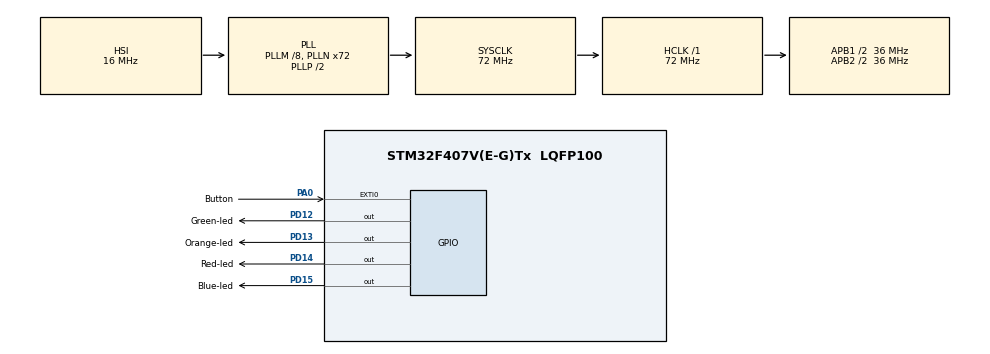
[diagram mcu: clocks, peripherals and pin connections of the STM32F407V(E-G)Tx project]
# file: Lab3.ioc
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Mcu.Family=STM32F4
Mcu.Name=STM32F407V(E-G)Tx
Mcu.Package=LQFP100
NVIC.EXTI0_IRQn=true\:1\:1\:true\:true\:true\:1\:true\:true\:true
NVIC.PriorityGroup=NVIC_PRIORITYGROUP_1
NVIC.TIM2_IRQn=true\:0\:0\:false\:true\:true\:2\:true\:true\:true
NVIC.TIM3_IRQn=true\:0\:0\:false\:true\:true\:3\:true\:true\:true
PA0-WKUP.GPIO_Label=Button
PA0-WKUP.Signal=GPXTI0
PD12.GPIO_Label=Green-led
PD12.Signal=GPIO_Output
PD13.GPIO_Label=Orange-led
PD13.Signal=GPIO_Output
PD14.GPIO_Label=Red-led
PD14.Signal=GPIO_Output
PD15.GPIO_Label=Blue-led
PD15.Signal=GPIO_Output
ProjectManager.HeapSize=0x200
ProjectManager.StackSize=0x400
ProjectManager.TargetToolchain=STM32CubeIDE
RCC.48MHZClocksFreq_Value=20571428.57142857
RCC.AHBFreq_Value=72000000
RCC.APB1CLKDivider=RCC_HCLK_DIV2
RCC.APB1Freq_Value=36000000
RCC.APB1TimFreq_Value=72000000
RCC.APB2CLKDivider=RCC_HCLK_DIV2
RCC.APB2Freq_Value=36000000
RCC.APB2TimFreq_Value=72000000
RCC.CortexFreq_Value=72000000
RCC.HCLKFreq_Value=72000000
RCC.HSE_VALUE=8000000
RCC.HSI_VALUE=16000000
RCC.LSE_VALUE=32768
RCC.PLLM=8
RCC.PLLN=72
RCC.PLLQ=7
RCC.SYSCLKFreq_VALUE=72000000
RCC.SYSCLKSource=RCC_SYSCLKSOURCE_PLLCLK
RCC.VCOOutputFreq_Value=144000000
TIM2.Period=2000
TIM2.Prescaler=35999
TIM3.Period=2000
TIM3.Prescaler=35999
VP_TIM2_VS_ClockSourceINT.Mode=Internal
VP_TIM3_VS_ClockSourceINT.Mode=Internal
board=STM32F407G-DISC1

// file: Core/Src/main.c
/* USER CODE BEGIN Header */
/**
  ******************************************************************************
  * @file           : main.c
  * @brief          : Main program body
  ******************************************************************************
  * @attention
  *
  * Copyright (c) 2024 STMicroelectronics.
  * All rights reserved.
  *
  * This software is licensed under terms that can be found in the LICENSE file
  * in the root directory of this software component.
  * If no LICENSE file comes with this software, it is provided AS-IS.
  *
  ******************************************************************************
  */
/* USER CODE END Header */
#include "main.h"

TIM_HandleTypeDef htim2;
TIM_HandleTypeDef htim3;

/* USER CODE BEGIN PV */
volatile int uzdNr = 3;
volatile int freq = 500;
/* USER CODE END PV */

void SystemClock_Config(void);
static void MX_GPIO_Init(void);
static void MX_TIM2_Init(void);
static void MX_TIM3_Init(void);
static void MX_NVIC_Init(void);

int main(void)
{

  /* MCU Configuration--------------------------------------------------------*/

  /* Reset of all peripherals, Initializes the Flash interface and the Systick. */
  HAL_Init();

  /* Configure the system clock */
  SystemClock_Config();

  /* Initialize all configured peripherals */
  MX_GPIO_Init();
  MX_TIM2_Init();
  MX_TIM3_Init();

  /* Initialize interrupts */
  MX_NVIC_Init();
  /* USER CODE BEGIN 2 */
  HAL_TIM_Base_Start_IT(&htim2);
  HAL_TIM_Base_Start_IT(&htim3);

  /* USER CODE END 2 */

  /* Infinite loop */
  /* USER CODE BEGIN WHILE */
  while (1)
  {
	  if(uzdNr == 2){
		  HAL_GPIO_WritePin(GPIOD, Orange_led_Pin, GPIO_PIN_SET);
		  HAL_Delay(freq);
		  HAL_GPIO_WritePin(GPIOD, Orange_led_Pin, GPIO_PIN_RESET);
		  HAL_Delay(freq);
	  }
    /* USER CODE END WHILE */

  }
}

void SystemClock_Config(void)
{
  RCC_OscInitTypeDef RCC_OscInitStruct = {0};
  RCC_ClkInitTypeDef RCC_ClkInitStruct = {0};

  /** Configure the main internal regulator output voltage
  */
  __HAL_RCC_PWR_CLK_ENABLE();
  __HAL_PWR_VOLTAGESCALING_CONFIG(PWR_REGULATOR_VOLTAGE_SCALE1);

  /** Initializes the RCC Oscillators according to the specified parameters
  * in the RCC_OscInitTypeDef structure.
  */
  RCC_OscInitStruct.OscillatorType = RCC_OSCILLATORTYPE_HSI;
  RCC_OscInitStruct.HSIState = RCC_HSI_ON;
  RCC_OscInitStruct.HSICalibrationValue = RCC_HSICALIBRATION_DEFAULT;
  RCC_OscInitStruct.PLL.PLLState = RCC_PLL_ON;
  RCC_OscInitStruct.PLL.PLLSource = RCC_PLLSOURCE_HSI;
  RCC_OscInitStruct.PLL.PLLM = 8;
  RCC_OscInitStruct.PLL.PLLN = 72;
  RCC_OscInitStruct.PLL.PLLP = RCC_PLLP_DIV2;
  RCC_OscInitStruct.PLL.PLLQ = 7;
  if (HAL_RCC_OscConfig(&RCC_OscInitStruct) != HAL_OK)
  {
    Error_Handler();
  }

  /** Initializes the CPU, AHB and APB buses clocks
  */
  RCC_ClkInitStruct.ClockType = RCC_CLOCKTYPE_HCLK|RCC_CLOCKTYPE_SYSCLK
                              |RCC_CLOCKTYPE_PCLK1|RCC_CLOCKTYPE_PCLK2;
  RCC_ClkInitStruct.SYSCLKSource = RCC_SYSCLKSOURCE_PLLCLK;
  RCC_ClkInitStruct.AHBCLKDivider = RCC_SYSCLK_DIV1;
  RCC_ClkInitStruct.APB1CLKDivider = RCC_HCLK_DIV2;
  RCC_ClkInitStruct.APB2CLKDivider = RCC_HCLK_DIV2;

  if (HAL_RCC_ClockConfig(&RCC_ClkInitStruct, FLASH_LATENCY_2) != HAL_OK)
  {
    Error_Handler();
  }
}

/**
  * @brief NVIC Configuration.
  * @retval None
  */
static void MX_NVIC_Init(void)
{
  /* EXTI0_IRQn interrupt configuration */
  HAL_NVIC_SetPriority(EXTI0_IRQn, 1, 1);
  HAL_NVIC_EnableIRQ(EXTI0_IRQn);
  /* TIM2_IRQn interrupt configuration */
  HAL_NVIC_SetPriority(TIM2_IRQn, 0, 0);
  HAL_NVIC_EnableIRQ(TIM2_IRQn);
  /* TIM3_IRQn interrupt configuration */
  HAL_NVIC_SetPriority(TIM3_IRQn, 0, 0);
  HAL_NVIC_EnableIRQ(TIM3_IRQn);
}

static void MX_TIM2_Init(void)
{

  TIM_ClockConfigTypeDef sClockSourceConfig = {0};
  TIM_MasterConfigTypeDef sMasterConfig = {0};

  htim2.Instance = TIM2;
  htim2.Init.Prescaler = 35999;
  htim2.Init.CounterMode = TIM_COUNTERMODE_UP;
  htim2.Init.Period = 2000; // 2000 - 1 sekunde
  htim2.Init.ClockDivision = TIM_CLOCKDIVISION_DIV1;
  htim2.Init.AutoReloadPreload = TIM_AUTORELOAD_PRELOAD_DISABLE;
  if (HAL_TIM_Base_Init(&htim2) != HAL_OK)
  {
    Error_Handler();
  }
  sClockSourceConfig.ClockSource = TIM_CLOCKSOURCE_INTERNAL;
  if (HAL_TIM_ConfigClockSource(&htim2, &sClockSourceConfig) != HAL_OK)
  {
    Error_Handler();
  }
  sMasterConfig.MasterOutputTrigger = TIM_TRGO_RESET;
  sMasterConfig.MasterSlaveMode = TIM_MASTERSLAVEMODE_DISABLE;
  if (HAL_TIMEx_MasterConfigSynchronization(&htim2, &sMasterConfig) != HAL_OK)
  {
    Error_Handler();
  }

}

static void MX_TIM3_Init(void)
{

  TIM_ClockConfigTypeDef sClockSourceConfig = {0};
  TIM_MasterConfigTypeDef sMasterConfig = {0};

  htim3.Instance = TIM3;
  htim3.Init.Prescaler = 35999;
  htim3.Init.CounterMode = TIM_COUNTERMODE_UP;
  htim3.Init.Period = 5000; // 2000 - 1 sekunde, tai 5000 = 2,5s
  htim3.Init.ClockDivision = TIM_CLOCKDIVISION_DIV1;
  htim3.Init.AutoReloadPreload = TIM_AUTORELOAD_PRELOAD_DISABLE;
  if (HAL_TIM_Base_Init(&htim3) != HAL_OK)
  {
    Error_Handler();
  }
  sClockSourceConfig.ClockSource = TIM_CLOCKSOURCE_INTERNAL;
  if (HAL_TIM_ConfigClockSource(&htim3, &sClockSourceConfig) != HAL_OK)
  {
    Error_Handler();
  }
  sMasterConfig.MasterOutputTrigger = TIM_TRGO_RESET;
  sMasterConfig.MasterSlaveMode = TIM_MASTERSLAVEMODE_DISABLE;
  if (HAL_TIMEx_MasterConfigSynchronization(&htim3, &sMasterConfig) != HAL_OK)
  {
    Error_Handler();
  }

}

static void MX_GPIO_Init(void)
{
  GPIO_InitTypeDef GPIO_InitStruct = {0};

  /* GPIO Ports Clock Enable */
  __HAL_RCC_GPIOA_CLK_ENABLE();
  __HAL_RCC_GPIOD_CLK_ENABLE();

  /*Configure GPIO pin Output Level */
  HAL_GPIO_WritePin(GPIOD, Green_led_Pin|Orange_led_Pin|Red_led_Pin|Blue_led_Pin, GPIO_PIN_RESET);

  /*Configure GPIO pin : Button_Pin */
  GPIO_InitStruct.Pin = Button_Pin;
  GPIO_InitStruct.Mode = GPIO_MODE_IT_RISING;
  GPIO_InitStruct.Pull = GPIO_NOPULL;
  HAL_GPIO_Init(Button_GPIO_Port, &GPIO_InitStruct);

  /*Configure GPIO pins : Green_led_Pin Orange_led_Pin Red_led_Pin Blue_led_Pin */
  GPIO_InitStruct.Pin = Green_led_Pin|Orange_led_Pin|Red_led_Pin|Blue_led_Pin;
  GPIO_InitStruct.Mode = GPIO_MODE_OUTPUT_PP;
  GPIO_InitStruct.Pull = GPIO_NOPULL;
  GPIO_InitStruct.Speed = GPIO_SPEED_FREQ_LOW;
  HAL_GPIO_Init(GPIOD, &GPIO_InitStruct);

}

void Error_Handler(void)
{
  __disable_irq();
  while (1)
  {
  }
}
